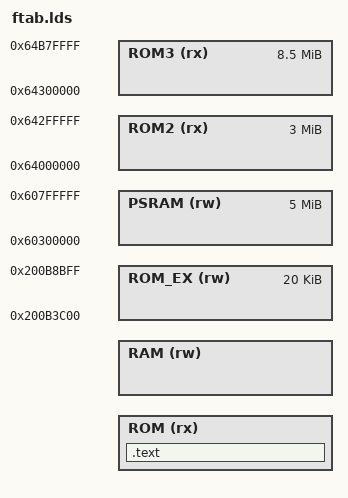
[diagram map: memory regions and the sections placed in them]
/******************************************************************************
 * @file     gcc_arm.ld
 * @brief    GNU Linker Script for Cortex-M based device
 * @version  V2.0.0
 * @date     21. May 2019
 ******************************************************************************/
#include "rtconfig.h"
#include "mem_map.h"
/*
 * Copyright (c) 2009-2019 Arm Limited. All rights reserved.
 *
 * SPDX-License-Identifier: Apache-2.0
 *
 * Licensed under the Apache License, Version 2.0 (the License); you may
 * not use this file except in compliance with the License.
 * You may obtain a copy of the License at
 *
 * www.apache.org/licenses/LICENSE-2.0
 *
 * Unless required by applicable law or agreed to in writing, software
 * distributed under the License is distributed on an AS IS BASIS, WITHOUT
 * WARRANTIES OR CONDITIONS OF ANY KIND, either express or implied.
 * See the License for the specific language governing permissions and
 * limitations under the License.
 */

/*
 *-------- <<< Use Configuration Wizard in Context Menu >>> -------------------
 */

/*---------------------- Flash Configuration ----------------------------------
  <h> Flash Configuration
    <o0> Flash Base Address <0x0-0xFFFFFFFF:8>
    <o1> Flash Size (in Bytes) <0x0-0xFFFFFFFF:8>
  </h>
  -----------------------------------------------------------------------------*/
__ROM_BASE = FLASH_TABLE_START_ADDR;
__ROM_SIZE = FLASH_TABLE_SIZE;

/*--------------------- Embedded RAM Configuration ----------------------------
  <h> RAM Configuration
    <o0> RAM Base Address    <0x0-0xFFFFFFFF:8>
    <o1> RAM Size (in Bytes) <0x0-0xFFFFFFFF:8>
  </h>
 -----------------------------------------------------------------------------*/
__RAM_BASE = HCPU_RAM_DATA_START_ADDR;
__RAM_SIZE = HCPU_RAM_DATA_SIZE;

/*--------------------- Stack / Heap Configuration ----------------------------
  <h> Stack / Heap Configuration
    <o0> Stack Size (in Bytes) <0x0-0xFFFFFFFF:8>
    <o1> Heap Size (in Bytes) <0x0-0xFFFFFFFF:8>
  </h>
  -----------------------------------------------------------------------------*/
__STACK_SIZE = 0x00002000;
__HEAP_SIZE  = 0x00000C00;

/*
 *-------------------- <<< end of configuration section >>> -------------------
 */
MEMORY
{
    ROM (rx) : ORIGIN = __ROM_BASE, LENGTH = __ROM_SIZE
    RAM (rw) : ORIGIN = __RAM_BASE, LENGTH = __RAM_SIZE
    ROM_EX(rw):ORIGIN = 0x200b3c00, LENGTH = 0x5000
    PSRAM(rw): ORIGIN = 0x60300000, LENGTH = 5M
    ROM2 (rx): ORIGIN = 0x64000000, LENGTH = 0x300000
    ROM3 (rx): ORIGIN = 0x64300000, LENGTH = 0x880000
}

/* Linker script to place sections and symbol values. Should be used together
 * with other linker script that defines memory regions FLASH and RAM.
 * It references following symbols, which must be defined in code:
 *   Reset_Handler : Entry of reset handler
 *
 * It defines following symbols, which code can use without definition:
 *   __exidx_start
 *   __exidx_end
 *   __copy_table_start__
 *   __copy_table_end__
 *   __zero_table_start__
 *   __zero_table_end__
 *   __etext
 *   __data_start__
 *   __preinit_array_start
 *   __preinit_array_end
 *   __init_array_start
 *   __init_array_end
 *   __fini_array_start
 *   __fini_array_end
 *   __data_end__
 *   __bss_start__
 *   __bss_end__
 *   __end__
 *   end
 *   __HeapLimit
 *   __StackLimit
 *   __StackTop
 *   __stack
 */
SECTIONS
{
  .text :
  {
    KEEP(*ftab.o(.text* .rodata*)) 
  } > ROM
}
